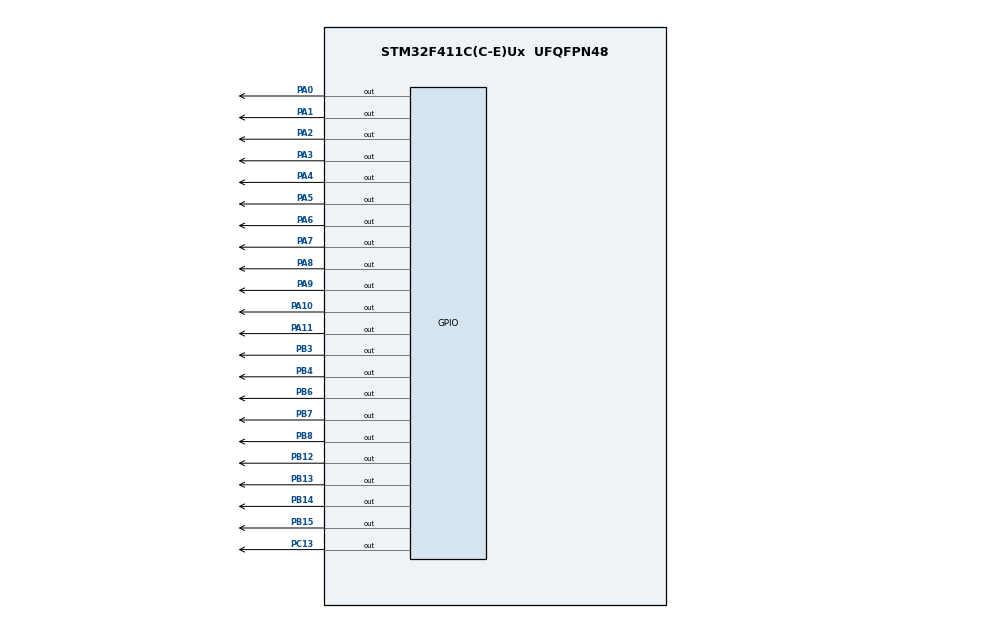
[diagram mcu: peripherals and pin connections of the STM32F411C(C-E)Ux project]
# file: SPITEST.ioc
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Mcu.Family=STM32F4
Mcu.Name=STM32F411C(C-E)Ux
Mcu.Package=UFQFPN48
NVIC.PriorityGroup=NVIC_PRIORITYGROUP_4
PA0-WKUP.Signal=GPIO_Output
PA1.Signal=GPIO_Output
PA10.Signal=GPIO_Output
PA11.Signal=GPIO_Output
PA2.Signal=GPIO_Output
PA3.Signal=GPIO_Output
PA4.Signal=GPIO_Output
PA5.Signal=GPIO_Output
PA6.Signal=GPIO_Output
PA7.Signal=GPIO_Output
PA8.Signal=GPIO_Output
PA9.Signal=GPIO_Output
PB12.Signal=GPIO_Output
PB13.Signal=GPIO_Output
PB14.Signal=GPIO_Output
PB15.Signal=GPIO_Output
PB3.Signal=GPIO_Output
PB4.Signal=GPIO_Output
PB6.Signal=GPIO_Output
PB7.Signal=GPIO_Output
PB8.Signal=GPIO_Output
PC13-ANTI_TAMP.Signal=GPIO_Output
PH0\ -\ OSC_IN.Mode=HSE-External-Oscillator
PH0\ -\ OSC_IN.Signal=RCC_OSC_IN
PH1\ -\ OSC_OUT.Mode=HSE-External-Oscillator
PH1\ -\ OSC_OUT.Signal=RCC_OSC_OUT
ProjectManager.HeapSize=0x200
ProjectManager.StackSize=0x400
ProjectManager.TargetToolchain=SW4STM32
RCC.48MHZClocksFreq_Value=50000000
RCC.AHBFreq_Value=100000000
RCC.APB1CLKDivider=RCC_HCLK_DIV2
RCC.APB1Freq_Value=50000000
RCC.APB1TimFreq_Value=100000000
RCC.APB2Freq_Value=100000000
RCC.APB2TimFreq_Value=100000000
RCC.CortexFreq_Value=100000000
RCC.HCLKFreq_Value=100000000
RCC.HSE_VALUE=25000000
RCC.HSI_VALUE=16000000
RCC.LSE_VALUE=32768
RCC.PLLM=12
RCC.PLLN=96
RCC.PLLSourceVirtual=RCC_PLLSOURCE_HSE
RCC.SYSCLKFreq_VALUE=100000000
RCC.SYSCLKSource=RCC_SYSCLKSOURCE_PLLCLK
RCC.VCOOutputFreq_Value=200000000
board=custom

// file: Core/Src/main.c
/* USER CODE BEGIN Header */
/**
  ******************************************************************************
  * @file           : main.c
  * @brief          : Main program body
  ******************************************************************************
  * @attention
  *
  * <h2><center>&copy; Copyright (c) 2021 STMicroelectronics.
  * All rights reserved.</center></h2>
  *
  * This software component is licensed by ST under BSD 3-Clause license,
  * the "License"; You may not use this file except in compliance with the
  * License. You may obtain a copy of the License at:
  *                        opensource.org/licenses/BSD-3-Clause
  *
  ******************************************************************************
  */
/* USER CODE END Header */
#include "main.h"

/* USER CODE BEGIN Includes */
#include "flash.h"
#include "ILI9341.h"
#include "nes.h"

/* USER CODE END Includes */

void SystemClock_Config(void);
static void MX_GPIO_Init(void);

int main(void)
{

  /* MCU Configuration--------------------------------------------------------*/

  /* Reset of all peripherals, Initializes the Flash interface and the Systick. */

  LL_APB2_GRP1_EnableClock(LL_APB2_GRP1_PERIPH_SYSCFG);
  LL_APB1_GRP1_EnableClock(LL_APB1_GRP1_PERIPH_PWR);

  NVIC_SetPriorityGrouping(NVIC_PRIORITYGROUP_4);

  /* System interrupt init*/

  /* Configure the system clock */
  SystemClock_Config();

  /* Initialize all configured peripherals */
  MX_GPIO_Init();
  /* USER CODE BEGIN 2 */
  ILI9341_Init();
  NES_Start();

  /* USER CODE END 2 */

  /* Infinite loop */
  while (1)
  {

    /* USER CODE BEGIN 3 */
      //刷屏测试
      //深蓝
//      LCD_WR_CLEAR(0x3A39);
      //橙色
//      LCD_WR_CLEAR(0xFBE4);
//      LCD_WR_CLEAR(COLOR_GREEN);
//      LCD_WR_CLEAR(COLOR_RED);
  }
  /* USER CODE END 3 */
}

void SystemClock_Config(void)
{
  LL_FLASH_SetLatency(LL_FLASH_LATENCY_3);
  while(LL_FLASH_GetLatency()!= LL_FLASH_LATENCY_3)
  {
  }
  LL_PWR_SetRegulVoltageScaling(LL_PWR_REGU_VOLTAGE_SCALE1);
  LL_RCC_HSE_Enable();

   /* Wait till HSE is ready */
  while(LL_RCC_HSE_IsReady() != 1)
  {

  }
  LL_RCC_PLL_ConfigDomain_SYS(LL_RCC_PLLSOURCE_HSE, LL_RCC_PLLM_DIV_10, 96, LL_RCC_PLLP_DIV_2);
  LL_RCC_PLL_Enable();

   /* Wait till PLL is ready */
  while(LL_RCC_PLL_IsReady() != 1)
  {

  }
  LL_RCC_SetAHBPrescaler(LL_RCC_SYSCLK_DIV_1);
  LL_RCC_SetAPB1Prescaler(LL_RCC_APB1_DIV_2);
  LL_RCC_SetAPB2Prescaler(LL_RCC_APB2_DIV_1);
  LL_RCC_SetSysClkSource(LL_RCC_SYS_CLKSOURCE_PLL);

   /* Wait till System clock is ready */
  while(LL_RCC_GetSysClkSource() != LL_RCC_SYS_CLKSOURCE_STATUS_PLL)
  {

  }
  LL_Init1msTick(100000000);
  LL_SetSystemCoreClock(100000000);
  LL_RCC_SetTIMPrescaler(LL_RCC_TIM_PRESCALER_TWICE);
}

static void MX_GPIO_Init(void)
{
  LL_GPIO_InitTypeDef GPIO_InitStruct = {0};

  /* GPIO Ports Clock Enable */
  LL_AHB1_GRP1_EnableClock(LL_AHB1_GRP1_PERIPH_GPIOC);
  LL_AHB1_GRP1_EnableClock(LL_AHB1_GRP1_PERIPH_GPIOH);
  LL_AHB1_GRP1_EnableClock(LL_AHB1_GRP1_PERIPH_GPIOA);
  LL_AHB1_GRP1_EnableClock(LL_AHB1_GRP1_PERIPH_GPIOB);

  /**/
  LL_GPIO_ResetOutputPin(GPIOC, LL_GPIO_PIN_13);

  /**/
  LL_GPIO_ResetOutputPin(GPIOA, LL_GPIO_PIN_0|LL_GPIO_PIN_1|LL_GPIO_PIN_2|LL_GPIO_PIN_3
                          |LL_GPIO_PIN_4|LL_GPIO_PIN_5|LL_GPIO_PIN_6|LL_GPIO_PIN_7
                          |LL_GPIO_PIN_8|LL_GPIO_PIN_9|LL_GPIO_PIN_10|LL_GPIO_PIN_11);

  /**/
  LL_GPIO_ResetOutputPin(GPIOB, LL_GPIO_PIN_12|LL_GPIO_PIN_13|LL_GPIO_PIN_14|LL_GPIO_PIN_15
                          |LL_GPIO_PIN_3|LL_GPIO_PIN_4|LL_GPIO_PIN_6|LL_GPIO_PIN_7
                          |LL_GPIO_PIN_8);

  /**/
  GPIO_InitStruct.Pin = LL_GPIO_PIN_13;
  GPIO_InitStruct.Mode = LL_GPIO_MODE_OUTPUT;
  GPIO_InitStruct.Speed = LL_GPIO_SPEED_FREQ_LOW;
  GPIO_InitStruct.OutputType = LL_GPIO_OUTPUT_PUSHPULL;
  GPIO_InitStruct.Pull = LL_GPIO_PULL_NO;
  LL_GPIO_Init(GPIOC, &GPIO_InitStruct);

  /**/
  GPIO_InitStruct.Pin = LL_GPIO_PIN_0|LL_GPIO_PIN_1|LL_GPIO_PIN_2|LL_GPIO_PIN_3
                          |LL_GPIO_PIN_4|LL_GPIO_PIN_5|LL_GPIO_PIN_6|LL_GPIO_PIN_7
                          |LL_GPIO_PIN_8|LL_GPIO_PIN_9|LL_GPIO_PIN_10|LL_GPIO_PIN_11;
  GPIO_InitStruct.Mode = LL_GPIO_MODE_OUTPUT;
  GPIO_InitStruct.Speed = LL_GPIO_SPEED_FREQ_LOW;
  GPIO_InitStruct.OutputType = LL_GPIO_OUTPUT_PUSHPULL;
  GPIO_InitStruct.Pull = LL_GPIO_PULL_NO;
  LL_GPIO_Init(GPIOA, &GPIO_InitStruct);

  /**/
  GPIO_InitStruct.Pin = LL_GPIO_PIN_12|LL_GPIO_PIN_13|LL_GPIO_PIN_14|LL_GPIO_PIN_15
                          |LL_GPIO_PIN_3|LL_GPIO_PIN_4|LL_GPIO_PIN_6|LL_GPIO_PIN_7
                          |LL_GPIO_PIN_8;
  GPIO_InitStruct.Mode = LL_GPIO_MODE_OUTPUT;
  GPIO_InitStruct.Speed = LL_GPIO_SPEED_FREQ_LOW;
  GPIO_InitStruct.OutputType = LL_GPIO_OUTPUT_PUSHPULL;
  GPIO_InitStruct.Pull = LL_GPIO_PULL_NO;
  LL_GPIO_Init(GPIOB, &GPIO_InitStruct);

}

void Error_Handler(void)
{
  __disable_irq();
  while (1) {
  }
}

/************************ (C) COPYRIGHT STMicroelectronics *****END OF FILE****/
